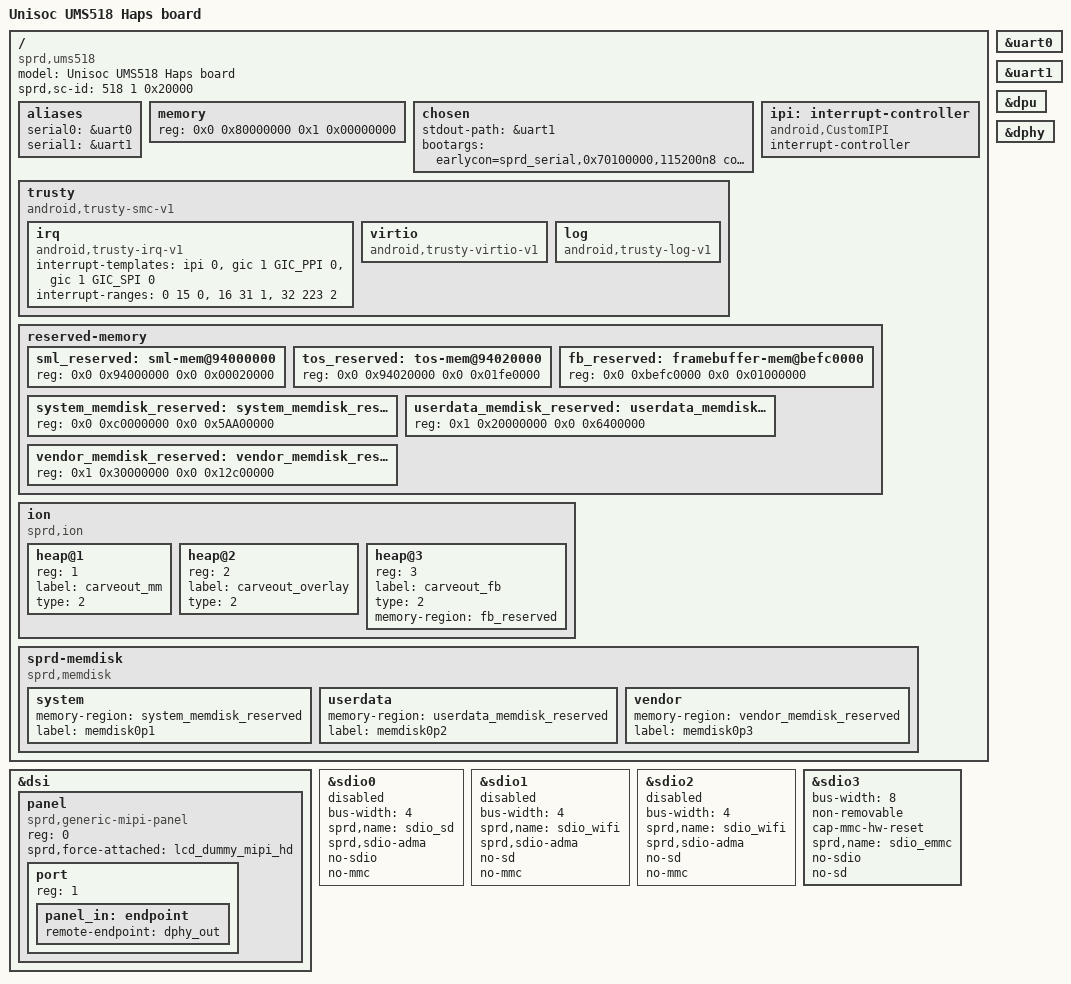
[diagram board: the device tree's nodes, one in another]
// SPDX-License-Identifier: (GPL-2.0+ OR MIT)
/*
 * Unisoc Sharkl5Pro platform DTS file
 *
 * Copyright (C) 2018, Unisoc Communications Inc.
 */

/dts-v1/;

#include "ums518-haps.dtsi"
#include "ums518-haps-common.dtsi"

/ {
	model = "Unisoc UMS518 Haps board";

	compatible = "sprd,ums518";

	sprd,sc-id = <518 1 0x20000>;

	aliases {
		serial0 = &uart0;
		serial1 = &uart1;
	};

	memory {
		device_type = "memory";
		reg = <0x0 0x80000000 0x1 0x00000000>;
	};

	chosen {
		stdout-path = &uart1;
		bootargs = "earlycon=sprd_serial,0x70100000,115200n8 console=ttyS1,115200n8 loglevel=11 maxcpus=1 init=/init root=/dev/memdisk0p1 rootfstype=ext4 rw rootwait androidboot.hardware=ums518_haps androidboot.selinux=permissive printk.devkmsg=on";
	};

	ipi: interrupt-controller {
		compatible = "android,CustomIPI";
		#interrupt-cells = <1>;
		interrupt-controller;
	};

	trusty {
		compatible = "android,trusty-smc-v1";
		irq {
			compatible = "android,trusty-irq-v1";
			interrupt-templates = <&ipi 0>,
				<&gic 1 GIC_PPI 0>,
				<&gic 1 GIC_SPI 0>;
			interrupt-ranges = < 0  15 0>,
					<16  31 1>,
					<32 223 2>;
		};

		virtio {
			compatible = "android,trusty-virtio-v1";
		};

		log {
			compatible = "android,trusty-log-v1";
		};
	};

	reserved-memory {
		#address-cells = <2>;
		#size-cells = <2>;
		ranges;

		sml_reserved: sml-mem@94000000{
			reg = <0x0 0x94000000 0x0 0x00020000>;
		};

		tos_reserved: tos-mem@94020000{
			reg = <0x0 0x94020000 0x0 0x01fe0000>;
		};

		fb_reserved: framebuffer-mem@befc0000{
			reg = <0x0 0xbefc0000 0x0 0x01000000>;
		};

		system_memdisk_reserved: system_memdisk_reserved@c0000000{
			reg = <0x0 0xc0000000 0x0 0x5AA00000>;  /* system 1536M */
		};

		userdata_memdisk_reserved: userdata_memdisk_reserved@120000000{
			reg = <0x1 0x20000000 0x0 0x6400000>; /* userdata 512M */
		};

		vendor_memdisk_reserved: vendor_memdisk_reserved@130000000{
			reg = <0x1 0x30000000 0x0 0x12c00000>; /* vendor 300M */
		};
	};

	ion {
		compatible = "sprd,ion";
		#address-cells = <1>;
		#size-cells = <0>;

		heap@1 {
			reg = <1>;
			label = "carveout_mm";
			type = <2>;
		};

		heap@2 {
			reg = <2>;
			label = "carveout_overlay";
			type = <2>;
			/* memory-region = <&overlay_reserved>;*/
		};

		heap@3 {
			reg = <3>;
			label = "carveout_fb";
			type = <2>;
			memory-region = <&fb_reserved>;
		};
	};

	sprd-memdisk {
		compatible = "sprd,memdisk";

		system {
			memory-region = <&system_memdisk_reserved>;
			label = "memdisk0p1";
		};

		userdata {
			memory-region = <&userdata_memdisk_reserved>;
			label = "memdisk0p2";
		};

		vendor {
			memory-region = <&vendor_memdisk_reserved>;
			label = "memdisk0p3";
		};
	};
};

&uart0 {
	status = "okay";
};

&uart1 {
	status = "okay";
};

&dpu {
	status = "okay";
};

&dsi {
	status = "okay";
	#address-cells = <1>;
	#size-cells = <0>;

	panel {
		compatible = "sprd,generic-mipi-panel";
		#address-cells = <1>;
		#size-cells = <0>;
		reg = <0>;

		sprd,force-attached = "lcd_dummy_mipi_hd";

		port {
			reg = <1>;
			panel_in: endpoint {
				remote-endpoint = <&dphy_out>;
			};
		};
	};
};

&dphy {
	status = "okay";
};

&sdio0 {
	bus-width = <4>;
	sprd,name = "sdio_sd";
	sprd,sdio-adma;
	no-sdio;
	no-mmc;
	status = "disabled";
};

&sdio1 {
	bus-width = <4>;
	sprd,name = "sdio_wifi";
	sprd,sdio-adma;
	no-sd;
	no-mmc;
	status = "disabled";
};

&sdio2 {
	bus-width = <4>;
	sprd,name = "sdio_wifi";
	sprd,sdio-adma;
	no-sd;
	no-mmc;
	status = "disabled";
};

&sdio3 {
	bus-width = <8>;
	non-removable;
	cap-mmc-hw-reset;
	sprd,name = "sdio_emmc";
	no-sdio;
	no-sd;
	status = "okay";
};
